# ATBTLC1000WLCSP register map
Vendor: Atmel Corp; Series: SAMB11; File version: TODO
CPU: CM0 r0p0, little endian, no MPU, no FPU, 2 interrupt priority bits
Address unit: 32 bits
Registers are 32-bit, read-write, reset 0x0 unless marked. A register's access mark holds for its fields unless they carry their own. Offsets are from the block's base; [hi:lo] are bit positions.

## AON_PWR_SEQ0 — Always On Power Sequencer
Base 0x4000E000
0x00 GPIO_WAKEUP_CTRL 8-bit reset 0x2 — Controls the wakeup enable for GPIO_0, GPIO_1 and GPIO_2 (Pinmux will control the ARM wakeup)
  [1] BLE_ENABLE — If set, this will enable GPIO_0 to wake up the BLE domain (PD4, PD5 and PD6)
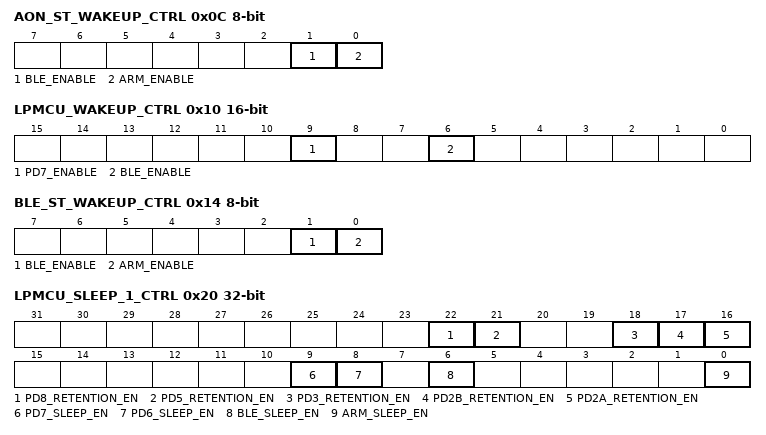
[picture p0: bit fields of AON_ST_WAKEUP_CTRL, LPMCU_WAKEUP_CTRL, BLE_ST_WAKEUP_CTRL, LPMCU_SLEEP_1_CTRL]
0x0C AON_ST_WAKEUP_CTRL 8-bit — Controls the wakeup enable for the Always On Sleep Timer (AON_ST)
  [1] BLE_ENABLE — If set, this will enable the AON_ST to wake up the BLE domain (PD4, PD5 and PD6)
  [0] ARM_ENABLE — If set, this will enable the AON_ST to wake up the ARM domain (PD1, PD2 and PD3)
0x10 LPMCU_WAKEUP_CTRL 16-bit — Controls the wakeup enable for the Low Power Micro Controller Unit (LPMCU)
  [9] PD7_ENABLE — If set, this will enable the LPMCU to wakeup the PD7 domain (EFUSE)
  [6] BLE_ENABLE — If set, this will enable the LPMCU to wake up the BLE domain (PD4, PD5 and PD6)
0x14 BLE_ST_WAKEUP_CTRL 8-bit — Controls the wakeup enable for the BLE Sleep Timer (BLE_ST)
  [1] BLE_ENABLE — If set, this will enable the BLE_ST to wake up the BLE domain
  [0] ARM_ENABLE — If set, this will enable the BLE_ST to wake up the ARM domain
0x20 LPMCU_SLEEP_1_CTRL — Controls the sleep and retention options for SLEEP request 1 from the ARM
  [22] PD8_RETENTION_EN — If 1, then PD8 will be put in retention mode when instructed to go to sleep (BLE LP Memory)
  [21] PD5_RETENTION_EN — If 1, then PD5 will be put in retention mode when instructed to go to sleep (BLE Retention Memory)
  [18] PD3_RETENTION_EN — If 1, then PD3 will be put in retention mode when instructed to go to sleep (Third, Fourth and Fifth ARM Memories 3x32K = 96K)
  [17] PD2B_RETENTION_EN — If 1, then PD2B will be put in retention mode when instructed to go to sleep (Second ARM Memory 16K)
  [16] PD2A_RETENTION_EN — If 1, then PD2A will be put in retention mode when instructed to go to sleep (First ARM Memory 16K)
  [9] PD7_SLEEP_EN — Enables the SLEEP request 1 to put PD7 domain in sleep (EFUSE)
  [8] PD6_SLEEP_EN — Enables the SLEEP request 1 to put PD6 domain in sleep (BLE Sleep Timer)
  [6] BLE_SLEEP_EN — Enables the SLEEP request 1 to put PD4 domain in sleep (BLE Core) and PD5 (BLE memories) in sleep or retention
  [0] ARM_SLEEP_EN — Enables the SLEEP request 1 to put all ARM domains in sleep or retention (PD1, PD2A, PD2B, PD3, PD8). PD7 has its own control
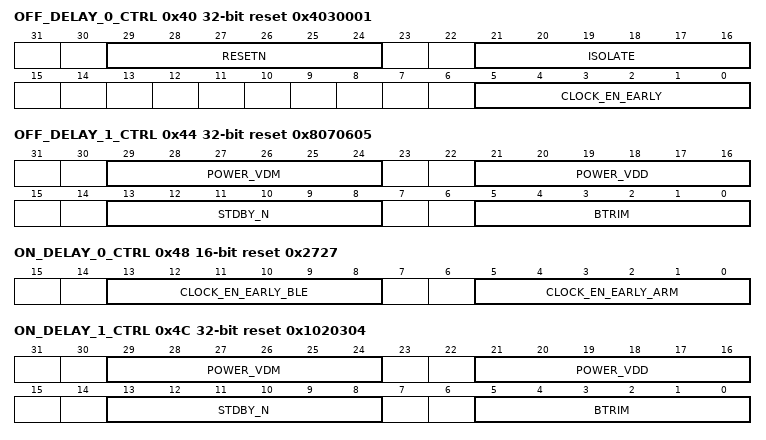
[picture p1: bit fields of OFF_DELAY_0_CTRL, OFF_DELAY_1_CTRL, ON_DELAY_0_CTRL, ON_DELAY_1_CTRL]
0x40 OFF_DELAY_0_CTRL reset 0x4030001 — Controls the delays for turning OFF power. Default order is: Disable clock_en_early (used for dividers) Disable clock_en (main clock branch) Isolate Assert RESETN Apply BTRIM Mux Select Apply STDBY_N (active low) Cut Off Power (VDD and standard cells) Cut Off or Lower VDM Power (Array Power Supply for memories)
  [29:24] RESETN — Number of clock cycles before asserting RESETN
  [21:16] ISOLATE — Number of clock cycles before enabling the isolation cells
  [5:0] CLOCK_EN_EARLY — Number of clock cycles before setting clock_en_early to low (clock_en is +1 of this value)
0x44 OFF_DELAY_1_CTRL reset 0x8070605 — Controls delays for turning OFF power
  [29:24] POWER_VDM — Number of clock cycles before cutting off or lowering power (VDM)
  [21:16] POWER_VDD — Number of clock cycles before cutting off power (VDD and standard cells)
  [13:8] STDBY_N — Number of clock cycles before applying STDBY_N
  [5:0] BTRIM — Number of clock cycles before applying BTRIM mux select
0x48 ON_DELAY_0_CTRL 16-bit reset 0x2727 — Controls the delays when turning ON power Default order is: Apply VDM Power (Memory Array) Apply VDD Power (VDD and standard cells) Remove STDBY_N Remove BTRIM Mux Select Remove Isolation De-assert RESETN Enable clock_en_early Enable clock_en
  [13:8] CLOCK_EN_EARLY_BLE — Number of clock cycles before setting clock_en_early to high for BLE domain clock_en is +1 of this value isolate is -2 of this value resetn is -1 of this value
  [5:0] CLOCK_EN_EARLY_ARM — Number of clock cycles before setting clock_en_early to high for ARM domain clock_en is +1 of this value isolate is -2 of this value resetn is -1 of this value
0x4C ON_DELAY_1_CTRL reset 0x1020304 — Controls delays for turning ON power
  [29:24] POWER_VDM — Number of clock cycles before applying VDM power
  [21:16] POWER_VDD — Number of clock cycles before applying VDD power
  [13:8] STDBY_N — Number of clock cycles before de-asserting the STDBY_N
  [5:0] BTRIM — Number of clock cycles before removing BTRIM mux select
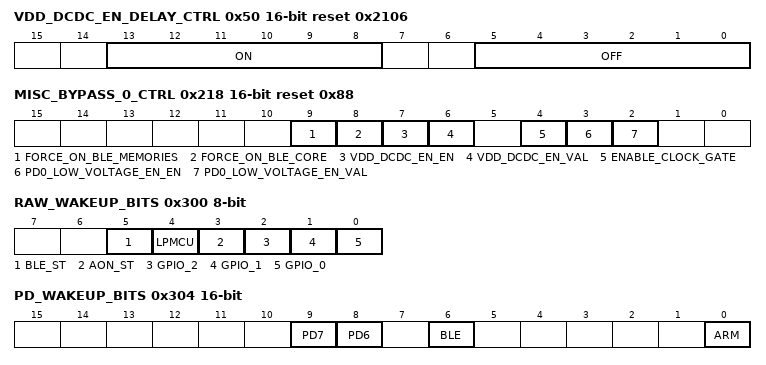
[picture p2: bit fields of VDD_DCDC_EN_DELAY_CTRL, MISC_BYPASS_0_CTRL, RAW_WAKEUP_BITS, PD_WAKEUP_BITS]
0x50 VDD_DCDC_EN_DELAY_CTRL 16-bit reset 0x2106 — Delay control for the vdd_dcdc_en signal (BLE domain only)
  [13:8] ON — Number of clock cycles before turning on the DCDC
  [5:0] OFF — Number of clock cycles before disabling the DCDC
0x218 MISC_BYPASS_0_CTRL 16-bit reset 0x88 — Bypass control for misc signals
  [9] FORCE_ON_BLE_MEMORIES — If set, this will keep the power enabled for the BLE memories (enables the DCDC operation)
  [8] FORCE_ON_BLE_CORE — If set, this will keep the power enabled for the BLE Core (enables the DCDC operation)
  [7] VDD_DCDC_EN_EN — Bypass enable for vdd_dcdc_en
  [6] VDD_DCDC_EN_VAL — Bypass value for vdd_dcdc_en
  [4] ENABLE_CLOCK_GATE — If set, allows the AON PS to gate its own clock while waiting for an event to enable it again
  [3] PD0_LOW_VOLTAGE_EN_EN — Bypass enable for pd0_low_voltage_en
  [2] PD0_LOW_VOLTAGE_EN_VAL — Bypass value for pd0_low_voltage_en
0x300 RAW_WAKEUP_BITS 8-bit ro
  [5] BLE_ST — BLE_ST wakeup raw status
  [4] LPMCU — LPMCU wakeup raw status
  [3] AON_ST — AON_ST wakeup raw status
  [2] GPIO_2 — AO_GPIO_2 wakeup raw status
  [1] GPIO_1 — AO_GPIO_1 wakeup raw status
  [0] GPIO_0 — AO_GPIO_0 wakeup raw status
0x304 PD_WAKEUP_BITS 16-bit ro — Individual Power Domain Wakeup Bits
  [9] PD7 — Indicates PD7 currently has a wakeup active
  [8] PD6 — Indicates PD6 currently has a wakeup active
  [6] BLE — Indicates BLE (PD4 and PD5) currently has a wakeup active
  [0] ARM — Indicates ARM (PD1, PD2A, PD2B, PD3, PD8) currently has a wakeup active
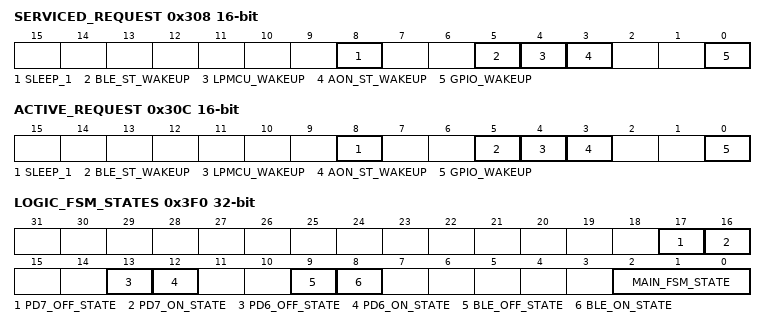
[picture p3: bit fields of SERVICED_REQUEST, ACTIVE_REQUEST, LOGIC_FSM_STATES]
0x308 SERVICED_REQUEST 16-bit ro — Serviced Request Status Bits
  [8] SLEEP_1 — Indicates SLEEP 1 has been serviced
  [5] BLE_ST_WAKEUP — Indicates BLE_ST wakeup has been serviced
  [4] LPMCU_WAKEUP — Indicates LPMCU wakeup has been serviced
  [3] AON_ST_WAKEUP — Indicates AON_ST wakeup has been serviced
  [0] GPIO_WAKEUP — Indicates GPIO wakeup has been serviced
0x30C ACTIVE_REQUEST 16-bit ro — Active Request Status Bits
  [8] SLEEP_1 — Indicates SLEEP 1 is the active request
  [5] BLE_ST_WAKEUP — Indicates BLE_ST wakeup is the active request
  [4] LPMCU_WAKEUP — Indicates LPMCU wakeup is the active request
  [3] AON_ST_WAKEUP — Indicates AON_ST wakeup is the active request
  [0] GPIO_WAKEUP — Indicates GPIO wakeup is the active request
0x3F0 LOGIC_FSM_STATES ro — Current Logic FSM States
  [17] PD7_OFF_STATE — If 1, then PD7 is OFF
  [16] PD7_ON_STATE — If 1, then PD7 is ON
  [13] PD6_OFF_STATE — If 1, then PD6 is OFF
  [12] PD6_ON_STATE — If 1, then PD6 is ON
  [9] BLE_OFF_STATE — If 1, then PD4 and PD5 are OFF (PD5 is in RET if set by ARM)
  [8] BLE_ON_STATE — If 1, then PD4 and PD5 are ON
  [2:0] MAIN_FSM_STATE
    0=RESET; 1=READY; 2=TRANS; 3=RESET_TO_READY; 4=READY_TO_TRANS; 5=TRANS_TO_READY
